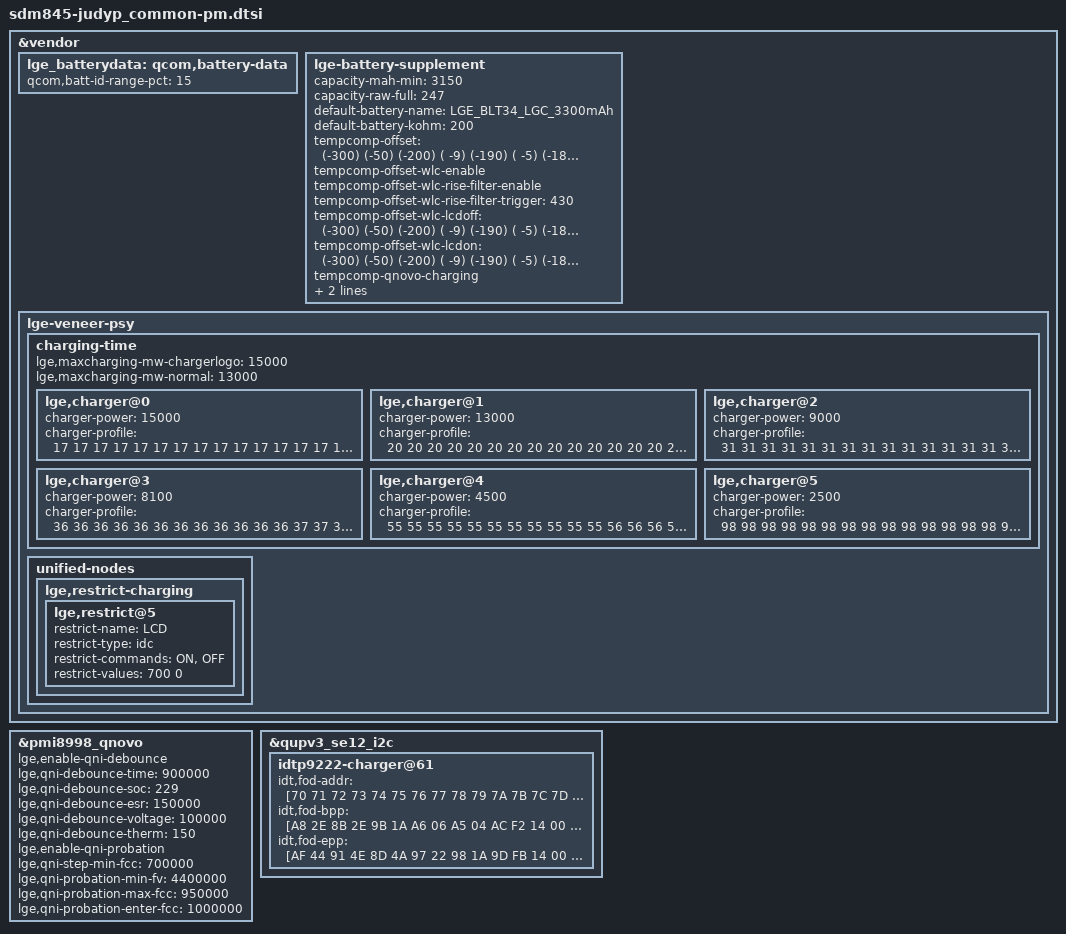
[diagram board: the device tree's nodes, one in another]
/* Copyright (c) 2017, The Linux Foundation. All rights reserved.
 *
 * This program is free software; you can redistribute it and/or modify
 * it under the terms of the GNU General Public License version 2 and
 * only version 2 as published by the Free Software Foundation.
 *
 * This program is distributed in the hope that it will be useful,
 * but WITHOUT ANY WARRANTY; without even the implied warranty of
 * MERCHANTABILITY or FITNESS FOR A PARTICULAR PURPOSE.  See the
 * GNU General Public License for more details.
 */

#include "../sdm845-judy_common/sdm845-judy_common-pm.dtsi"

&vendor {
	lge_batterydata: qcom,battery-data {
		qcom,batt-id-range-pct = <15>;

		#include "../../sdm845-battery/LGE_BLT34_LGC_3300mAh.dtsi"
	};

	lge-battery-supplement {
		capacity-mah-min = <3150>;
		capacity-raw-full = <247>;

		default-battery-name = "LGE_BLT34_LGC_3300mAh";
		default-battery-kohm = <200>;

		/* format : (temp index) (temp delta) */
		tempcomp-offset = <
			(-300) (-50)
			(-200) ( -9)
			(-190) ( -5)
			(-180)    0
			(-170)    5
			(-160)   10
			(-150)   12
			(-100)   27
			(-50)    35
			0        37
			50       25
			100      22
			150      14
			200       4
			250    ( -7)
			300    (-19)
			350    (-30)
			400    (-36)
			450    (-44)
			500    (-64)
			550    (-36)
			600    (-31)
			700    (-10)
			800    (-10)
			900    (-10)
		>;

		tempcomp-offset-wlc-enable;
		tempcomp-offset-wlc-rise-filter-enable;
		tempcomp-offset-wlc-rise-filter-trigger = <430>;
		tempcomp-offset-wlc-lcdoff = <
			(-300) (-50)
			(-200) ( -9)
			(-190) ( -5)
			(-180)    0
			(-170)    5
			(-160)   10
			(-150)   12
			(-100)   27
			(-50)    35
			0        37
			50       25
			100      22
			150      14
			200       4
			250    ( -7)
			300    (-19)
			350    (-18)
			400    (-17)
			450    (-21)
			500    (-23)
			550    (-15)
			600    (-10)
			700    (-10)
			800    (-10)
			900    (-10)
		>;

		tempcomp-offset-wlc-lcdon = <
			(-300) (-50)
			(-200) ( -9)
			(-190) ( -5)
			(-180)    0
			(-170)    5
			(-160)   10
			(-150)   12
			(-100)   27
			(-50)    35
			0        37
			50       25
			100      22
			150      14
			200       4
			250    ( -7)
			300    (-19)
			350    (-30)
			400    (-36)
			450    (-44)
			500    (-64)
			550    (-36)
			600    (-31)
			700    (-10)
			800    (-10)
			900    (-10)
		>;

		tempcomp-qnovo-charging;
		lg-monotonic-soc-enable;

		tempcomp-icoeff = <100>;
	};

	lge-veneer-psy {
		charging-time {
			#address-cells = <1>;
			#size-cells = <0>;

			lge,maxcharging-mw-chargerlogo = <15000>;
			lge,maxcharging-mw-normal = <13000>;

			lge,charger@0 {		//  power-off fast charger: 9V * 1.6A or 5V * 3A = 15W
				charger-power = <15000>;
				charger-profile = <
					17  17  17  17  17  17  17  17  17  17  17  17  17  17  17  17
					17  17  17  17  17  17  17  17  17  17  17  17  17  17  17  17
					17  17  17  17  17  17  17  17  17  17  17  17  17  17  17  17
					17  17  17  17  17  17  17  17  17  17  17  17  17  17  17  17
					17  17  17  17  17  17  17  17  17  17  17  17  17  17  17  17
					17  17  17  17  17  17  17  17  17  17  17  17  17  17  17  17
					17  17  17  17  17  17  17  17  17  17  17  17  17  17  17  17
					17  17  17  17  17  17  17  17  17  17  17  17  17  17  17  17
					17  17  17  17  17  17  17  17  17  17  17  17  17  17  17  17
					17  17  17  17  17  17  17  17  17  17  17  17  17  17  17  17
					17  17  17  17  17  17  17  17  17  17  17  17  17  17  17  17
					17  17  17  17  17  19  19  19  19  19  19  19  19  19  19  19
					19  22  22  22  22  22  22  22  22  22  22  22  22  26  26  26
					26  26  26  26  32  32  32  32  32  32  32  32  32  32  40  40
					40  40  40  40  52  52  52  52  52  52  65  65  65  65  65  65
					70  75  80  90 100 105 105 105 105 105 105 105 105 105 105 105
				>;
			};
			lge,charger@1 {		//  power-on fast charger: 2.6A * 4.0V / 80% = 13W
				charger-power = <13000>;
				charger-profile = <
					20  20  20  20  20  20  20  20  20  20  20  20  20  20  20  20
					20  20  20  20  20  20  20  20  20  20  20  20  20  20  20  20
					20  20  20  20  20  20  20  20  20  20  20  20  20  20  20  20
					20  20  20  20  20  20  20  20  20  20  20  20  20  20  20  20
					20  20  20  20  20  20  20  20  20  20  20  20  20  20  20  20
					20  20  20  20  20  20  20  20  20  20  20  20  20  20  20  20
					20  20  20  20  20  20  20  20  20  20  20  20  20  20  20  20
					20  20  20  20  20  20  20  20  20  20  20  20  20  20  20  20
					20  20  20  20  20  20  20  20  20  20  20  20  20  20  20  20
					20  20  20  20  20  20  20  20  20  20  20  20  20  20  20  20
					20  20  20  20  20  20  20  20  20  20  20  20  20  20  20  20
					20  20  20  20  20  20  20  20  20  20  20  20  20  20  20  20
					20  22  22  22  22  22  22  22  22  22  22  22  22  26  26  26
					26  26  26  26  32  32  32  32  32  32  32  32  32  32  40  40
					40  43  43  44  45  52  52  52  52  52  65  65  65  65  65  65
					70  75  80  90 100 105 105 105 105 105 105 105 105 105 105 105
				>;
			};
			lge,charger@2 {		//  dcp: 1.8A * 5V = 9W
				charger-power = <9000>;
				charger-profile = <
					31  31  31  31  31  31  31  31  31  31  31  31  31  31  31  31
					31  31  31  31  31  31  31  31  31  31  31  31  31  31  31  31
					31  31  31  31  31  31  31  31  31  31  31  31  31  31  31  31
					31  31  31  31  31  31  31  31  31  31  31  31  31  31  31  31
					31  31  31  31  31  31  31  31  31  31  31  31  31  31  31  31
					31  31  31  31  31  31  31  31  31  31  31  31  31  31  31  31
					31  31  31  31  31  31  31  31  31  31  31  31  31  31  31  31
					31  31  31  31  31  31  31  31  31  31  31  31  31  31  31  31
					31  31  31  31  31  31  31  31  31  31  31  31  31  31  31  31
					31  31  31  31  31  31  31  31  31  31  31  31  31  31  31  31
					31  31  31  31  31  31  31  31  31  31  31  31  31  31  31  31
					31  31  31  31  31  31  31  31  31  31  31  31  31  31  31  31
					31  31  31  31  31  31  31  31  31  31  31  31  31  31  31  31
					31  31  31  31  34  34  34  34  34  34  34  34  34  34  42  42
					42  42  42  42  55  55  55  55  55  55  69  69  69  69  69  69
					70  75  80  90 100 105 105 105 105 105 105 105 105 105 105 105
				>;
			};
			lge,charger@3 {		// EPP wireless charger: 9000mV * 900mA = 8.1W
				charger-power = <8100>;
				charger-profile = <
					36  36  36  36  36  36  36  36  36  36  36  36  37  37  37  37
					37  37  37  37  37  37  37  37  37  37  38  38  38  38  38  38
					38  38  38  38  38  38  38  38  39  39  39  39  39  39  39  39
					39  39  39  39  40  40  40  40  40  40  40  40  40  40  40  40
					41  41  41  41  41  41  41  41  41  41  41  41  42  42  42  42
					42  42  42  42  42  42  42  43  43  43  43  43  43  43  43  43
					43  44  44  44  44  44  44  44  44  44  44  45  45  45  45  45
					45  45  45  45  46  46  46  46  46  46  46  46  46  47  47  47
					47  47  47  47  47  47  48  48  48  48  48  48  48  48  49  49
					49  49  49  49  49  49  50  50  50  50  50  50  50  50  51  51
					51  51  51  51  51  52  52  52  52  52  52  52  53  53  53  53
					53  53  53  54  54  54  54  54  54  54  55  55  55  55  55  55
					56  56  56  56  56  56  57  57  57  57  57  57  58  58  58  58
					58  58  59  59  59  59  59  60  60  60  60  60  61  61  61  61
					61  61  62  62  62  62  60  60  60  60  60  60  60  60  60  60
					70  75  80  90 100 105 105 105 105 105 105 105 105 105 105 105
				>;
			};
			lge,charger@4 {		// BPP wireless charger: 5000mV * 900mA = 4.5W
				charger-power = <4500>;
				charger-profile = <
					55  55  55  55  55  55  55  55  55  55  55  56  56  56  56  56
					56  56  56  56  56  56  56  56  56  56  56  56  56  56  56  56
					56  56  56  56  56  56  56  56  56  57  57  57  57  57  57  57
					57  57  57  57  57  57  57  57  57  57  57  57  57  57  57  57
					57  57  57  57  57  57  57  58  58  58  58  58  58  58  58  58
					58  58  58  58  58  58  58  58  58  58  58  58  58  58  58  58
					58  58  58  59  59  59  59  59  59  59  59  59  59  59  59  59
					59  59  59  59  59  59  59  59  59  59  59  59  59  59  59  60
					60  60  60  60  60  60  60  60  60  60  60  60  60  60  60  60
					60  60  60  60  60  60  60  60  60  61  61  61  61  61  61  61
					61  61  61  61  61  61  61  61  61  61  61  61  61  61  61  61
					61  61  61  62  62  62  62  62  62  62  62  62  62  62  62  62
					62  62  62  62  62  62  62  62  62  62  62  63  63  63  63  63
					63  63  63  63  63  63  63  63  63  63  63  63  60  60  60  60
					60  60  60  60  60  60  60  60  60  60  60  65  65  65  65  65
					70  75  80  90 100 105 105 105 105 105 105 105 105 105 105 105
				>;
			};
			lge,charger@5 {		// SDP: 5000mV * 500mA = 2.5W
				charger-power = <2500>;
				charger-profile = <
					98  98  98  98  98  98  98  98  98  98  98  98  98  98  98  98
					98  98  98  98  98  98  98  98  98  98  98  98  98  98  98  98
					98  98  98  98  98  98  98  98  98  98  98  98  98  98  98  98
					98  98  98  98  98  98  98  98  98  98  98  98  98  98  98  98
					98  98  98  98  98  98  98  98  98  98  98  98  98  98  98  98
					98  98  98  98  98  98  98  98  98  98  98  98  98  98  98  98
					98  98  98  98  98  98  98  98  98  98  98  98  98  98  98  98
					98  98  98  98  98  98  98  98  98  98  98  98  98  98  98  98
					98  98  98  98  98  98  98  98  98  98  98  98  98  98  98  98
					98  98  98  98  98  98  98  98  98  98  98  98  98  98  98  98
					98  98  98  98  98  98  98  98  98  98  98  98  98  98  98  98
					98  98  98  98  98  98  98  98  98  98  98  98  98  98  98  98
					98  98  98  98  98  98  98  98  98  98  98  98  98  98  98  98
					98  98  98  98  98  98  98  98  98  98  98  98  98  98  98  98
					98  98  98  98  98  98  98  98  98  98  98  98  98  98  98  98
					98  98  98  98  98 110 110 110 110 110 110 110 110 110 110 110
				>;
			};
		};

		unified-nodes {
			lge,restrict-charging {
				lge,restrict@5 {
					restrict-name = "LCD";
					restrict-type = "idc";
					restrict-commands = "ON", "OFF";
					restrict-values = < 700      0>;
				};
			};
		};
	};
};

&pmi8998_qnovo {
	lge,enable-qni-debounce;
	lge,qni-debounce-time = <900000>;
	lge,qni-debounce-soc = <229>;
	lge,qni-debounce-esr = <150000>;
	lge,qni-debounce-voltage = <100000>;
	lge,qni-debounce-therm = <150>;

	lge,enable-qni-probation;
	lge,qni-step-min-fcc = <700000>;
	lge,qni-probation-min-fv = <4400000>;
	lge,qni-probation-max-fcc = <950000>;
	lge,qni-probation-enter-fcc = <1000000>;
};

&qupv3_se12_i2c {
	idtp9222-charger@61 {
		// FOD parameters
		idt,fod-addr = [70 71 72 73 74 75 76 77 78 79 7A 7B 7C 7D 7E 7F];
		idt,fod-bpp  = [A8 2E 8B 2E 9B 1A A6 06 A5 04 AC F2 14 00 00 00];
		idt,fod-epp  = [AF 44 91 4E 8D 4A 97 22 98 1A 9D FB 14 00 64 32];
	};
};

